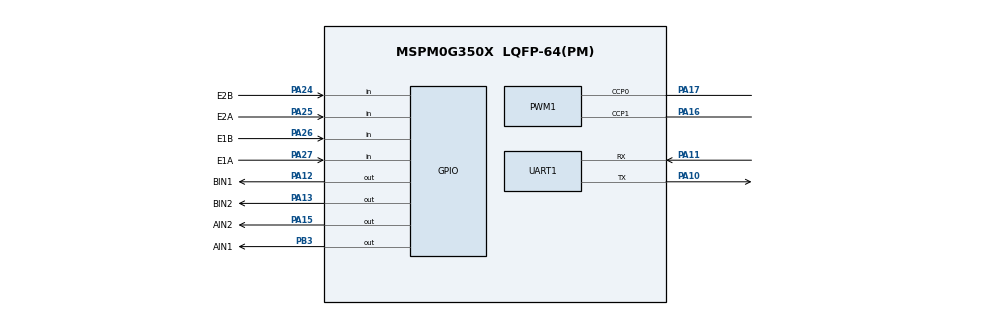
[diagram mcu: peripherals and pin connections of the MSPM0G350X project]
/**
 * @cliArgs --device "MSPM0G350X" --part "Default" --package "LQFP-64(PM)" --product "mspm0_sdk@2.10.00.04"
 * @versions {"tool":"1.27.0+4565"}
 */

/**
 * Import the modules used in this configuration.
 */
const GPIO   = scripting.addModule("/ti/driverlib/GPIO", {}, false);
const GPIO1  = GPIO.addInstance();
const GPIO2  = GPIO.addInstance();
const PWM    = scripting.addModule("/ti/driverlib/PWM", {}, false);
const PWM1   = PWM.addInstance();
const SYSCTL = scripting.addModule("/ti/driverlib/SYSCTL");
const TIMER  = scripting.addModule("/ti/driverlib/TIMER", {}, false);
const TIMER1 = TIMER.addInstance();
const UART   = scripting.addModule("/ti/driverlib/UART", {}, false);
const UART1  = UART.addInstance();

/**
 * Write custom configuration values to the imported modules.
 */
GPIO1.$name                               = "ENCODER";
GPIO1.port                                = "PORTA";
GPIO1.associatedPins.create(4);
GPIO1.associatedPins[0].$name             = "E1A";
GPIO1.associatedPins[0].direction         = "INPUT";
GPIO1.associatedPins[0].interruptEn       = true;
GPIO1.associatedPins[0].polarity          = "RISE";
GPIO1.associatedPins[0].internalResistor  = "PULL_DOWN";
GPIO1.associatedPins[0].interruptPriority = "0";
GPIO1.associatedPins[0].assignedPin       = "27";
GPIO1.associatedPins[0].pin.$assign       = "PA27";
GPIO1.associatedPins[1].$name             = "E1B";
GPIO1.associatedPins[1].direction         = "INPUT";
GPIO1.associatedPins[1].interruptEn       = true;
GPIO1.associatedPins[1].polarity          = "RISE";
GPIO1.associatedPins[1].internalResistor  = "PULL_DOWN";
GPIO1.associatedPins[1].interruptPriority = "0";
GPIO1.associatedPins[1].assignedPin       = "26";
GPIO1.associatedPins[1].pin.$assign       = "PA26";
GPIO1.associatedPins[2].$name             = "E2A";
GPIO1.associatedPins[2].direction         = "INPUT";
GPIO1.associatedPins[2].interruptEn       = true;
GPIO1.associatedPins[2].polarity          = "RISE";
GPIO1.associatedPins[2].internalResistor  = "PULL_DOWN";
GPIO1.associatedPins[2].interruptPriority = "0";
GPIO1.associatedPins[2].assignedPin       = "25";
GPIO1.associatedPins[2].pin.$assign       = "PA25";
GPIO1.associatedPins[3].$name             = "E2B";
GPIO1.associatedPins[3].direction         = "INPUT";
GPIO1.associatedPins[3].interruptEn       = true;
GPIO1.associatedPins[3].polarity          = "RISE";
GPIO1.associatedPins[3].internalResistor  = "PULL_DOWN";
GPIO1.associatedPins[3].interruptPriority = "0";
GPIO1.associatedPins[3].assignedPin       = "24";
GPIO1.associatedPins[3].pin.$assign       = "PA24";

const Board = scripting.addModule("/ti/driverlib/Board", {}, false);

GPIO2.$name                          = "MOTOR";
GPIO2.associatedPins.create(4);
GPIO2.associatedPins[0].$name        = "AIN1";
GPIO2.associatedPins[0].assignedPort = "PORTB";
GPIO2.associatedPins[0].assignedPin  = "3";
GPIO2.associatedPins[0].pin.$assign  = "PB3";
GPIO2.associatedPins[1].$name        = "AIN2";
GPIO2.associatedPins[1].assignedPort = "PORTA";
GPIO2.associatedPins[1].assignedPin  = "15";
GPIO2.associatedPins[1].pin.$assign  = "PA15";
GPIO2.associatedPins[2].$name        = "BIN1";
GPIO2.associatedPins[2].assignedPort = "PORTA";
GPIO2.associatedPins[2].assignedPin  = "12";
GPIO2.associatedPins[2].pin.$assign  = "PA12";
GPIO2.associatedPins[3].$name        = "BIN2";
GPIO2.associatedPins[3].assignedPort = "PORTA";
GPIO2.associatedPins[3].assignedPin  = "13";
GPIO2.associatedPins[3].pin.$assign  = "PA13";

PWM1.$name                              = "PWM_MOTOR";
PWM1.timerStartTimer                    = true;
PWM1.pwmMode                            = "EDGE_ALIGN_UP";
PWM1.peripheral.$assign                 = "TIMA1";
PWM1.peripheral.ccp0Pin.$assign         = "PA17";
PWM1.peripheral.ccp1Pin.$assign         = "PA16";
PWM1.PWM_CHANNEL_0.$name                = "ti_driverlib_pwm_PWMTimerCC0";
PWM1.PWM_CHANNEL_0.ccValue              = 500;
PWM1.PWM_CHANNEL_1.$name                = "ti_driverlib_pwm_PWMTimerCC1";
PWM1.PWM_CHANNEL_1.ccValue              = 500;
PWM1.ccp0PinConfig.direction            = scripting.forceWrite("OUTPUT");
PWM1.ccp0PinConfig.hideOutputInversion  = scripting.forceWrite(false);
PWM1.ccp0PinConfig.onlyInternalResistor = scripting.forceWrite(false);
PWM1.ccp0PinConfig.passedPeripheralType = scripting.forceWrite("Digital");
PWM1.ccp0PinConfig.$name                = "ti_driverlib_gpio_GPIOPinGeneric4";
PWM1.ccp1PinConfig.direction            = scripting.forceWrite("OUTPUT");
PWM1.ccp1PinConfig.hideOutputInversion  = scripting.forceWrite(false);
PWM1.ccp1PinConfig.onlyInternalResistor = scripting.forceWrite(false);
PWM1.ccp1PinConfig.passedPeripheralType = scripting.forceWrite("Digital");
PWM1.ccp1PinConfig.$name                = "ti_driverlib_gpio_GPIOPinGeneric5";

SYSCTL.forceDefaultClkConfig = true;

TIMER1.timerMode          = "PERIODIC";
TIMER1.interrupts         = ["ZERO"];
TIMER1.timerStartTimer    = true;
TIMER1.$name              = "TIMER_ENCODER";
TIMER1.timerClkDiv        = 8;
TIMER1.interruptPriority  = "0";
TIMER1.timerClkPrescale   = 10;
TIMER1.timerPeriod        = "10 ms";
TIMER1.peripheral.$assign = "TIMA0";

UART1.$name                    = "UART_0";
UART1.enabledInterrupts        = ["RX"];
UART1.interruptPriority        = "0";
UART1.peripheral.$assign       = "UART0";
UART1.peripheral.rxPin.$assign = "PA11";
UART1.peripheral.txPin.$assign = "PA10";
UART1.txPinConfig.$name        = "ti_driverlib_gpio_GPIOPinGeneric0";
UART1.rxPinConfig.$name        = "ti_driverlib_gpio_GPIOPinGeneric1";

/**
 * Pinmux solution for unlocked pins/peripherals. This ensures that minor changes to the automatic solver in a future
 * version of the tool will not impact the pinmux you originally saw.  These lines can be completely deleted in order to
 * re-solve from scratch.
 */
Board.peripheral.$suggestSolution          = "DEBUGSS";
Board.peripheral.swclkPin.$suggestSolution = "PA20";
Board.peripheral.swdioPin.$suggestSolution = "PA19";
SYSCTL.peripheral.$suggestSolution         = "SYSCTL";
